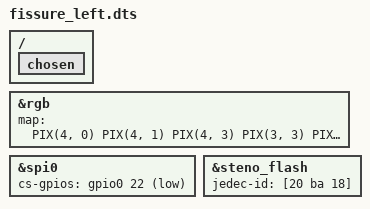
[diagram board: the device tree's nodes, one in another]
#include "fissure.dtsi"
#include "dt-bindings/zmk/is31fl3729_transform.h"
#include "fissure_left-pinctrl.dtsi"

/ {
    chosen {
    };
};

#define RGB_CS0 3, 2, 1
#define RGB_CS1 6, 5, 4
#define RGB_CS2 9, 8, 7
#define RGB_CS3 15, 14, 13
#define RGB_CS4 12, 11, 10
&rgb {
    map = <
PIX(4, 0) PIX(4, 1) PIX(4, 3) PIX(3, 3) PIX(2, 3) PIX(1, 3)
PIX(3, 0) PIX(2, 0) PIX(4, 2) PIX(4, 4) PIX(2, 2) PIX(1, 2)
          PIX(1, 0) PIX(3, 1) PIX(3, 2) PIX(2, 1) PIX(1, 1)
                              PIX(3, 4) PIX(2, 4) PIX(1, 4)
        >;
};

&spi0 {
    cs-gpios = <&gpio0 22 GPIO_ACTIVE_LOW>;
};

&steno_flash {
    jedec-id = [20 ba 18];      // TODO
};
